# D1H.pdf register map
Vendor: Allwinner; Series: D1H.pdf; File version: 0.1
CPU: XuanTie C906 RISC-V CPU 0, little endian, MPU, FPU, double-precision FPU, 0 interrupt priority bits
Registers are 32-bit, read-write, reset 0x0 unless marked. A register's access mark holds for its fields unless they carry their own. Offsets are from the block's base; [hi:lo] are bit positions; {n}, {i} and the like mark numbered series.

## RTC
Base 0x07090000
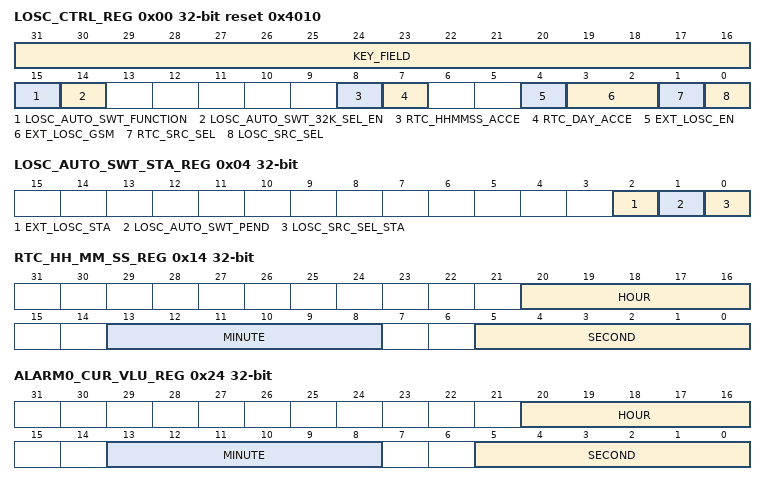
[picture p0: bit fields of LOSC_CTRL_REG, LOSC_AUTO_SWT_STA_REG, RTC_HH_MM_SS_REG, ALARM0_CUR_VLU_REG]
0x00 LOSC_CTRL_REG reset 0x4010 — Low Oscillator Control Register
  [31:16] KEY_FIELD wo — Key Field This field should be filled with 0x16AA, and then the bit0 and bit1 can be written with the new value.
  [15] LOSC_AUTO_SWT_FUNCTION — LOSC auto switch function disable 0: Enable 1: Disable
    0=Enable; 1=Disable
  [14] LOSC_AUTO_SWT_32K_SEL_EN — LOSC auto switch 32K clk source select enable 0: Disable. When the losc losts, the 32k clk source will not change to RC 1: Enable. When the losc losts, the 32k clk source will change to RC (LOSC_SRC_SEL will be changed from 1 to 0)
    0=Disable. When the losc losts, the 32k clk source will not change to RC; 1=Enable. When the losc losts, the 32k clk source will change to RC (LOSC_SRC_SEL will be changed from 1 to 0)
  [8] RTC_HHMMSS_ACCE — RTC Hour Minute Second access After writing the RTC HH-MM-SS Register, this bit is set and it will be cleared until the real writing operation is finished. After writing the RTC HH-MM-SS Register, the RTC HH-MM-SS Register will be refreshed for at most one second. Note: Make sure that the bit is 0 for time configuration.
  [7] RTC_DAY_ACCE — RTC DAY access After writing the RTC DAY register, this bit is set and it will be cleared until the real writing operation is finished. After writing the RTC DAY register, the DAY register will be refreshed for at most one second. Note: Make sure that the bit is 0 for time configuration.
  [4] EXT_LOSC_EN — External 32.768 kHz Crystal Enable 0: Disable 1: Enable
    0=Disable; 1=Enable
  [3:2] EXT_LOSC_GSM — External 32.768 kHz Crystal GSM 00: Low 01: / 10: / 11: High When GSM is changed, the 32K oscillation circuit will arise transient instability. If the autoswitch function (bit 15) is enabled, 32K changes to RC16M with certain probability. The GSM can influence the time of 32K starting oscillation, the more the GSM, the shorter the time of starting oscillation. So modifying GSM is not recommended. If you need to modify the GSM, firstly disable the auto switch function (bit 15), with a delay of 50 us, then change the GSM, the 32K clock source is changed to external clock.
    0=Low; 3=High When GSM is changed, the 32K oscillation circuit will arise transient instability. If the autoswitch function (bit 15) is enabled, 32K changes to RC16M with certain probability. The GSM can influence the time of 32K starting oscillation, the more the GSM, the shorter the time of starting oscillation. So modifying GSM is not recommended. If you need to modify the GSM, firstly disable the auto switch function (bit 15), with a delay of 50 us, then change the GSM, the 32K clock source is changed to external clock.
  [1] RTC_SRC_SEL — RTC_TIMER Clock Source Select 0: LOSC_SRC 1: 24MDIV32K Before switching the bit, make sure that the 24MDIV32K function is enabled, that is, the bit16 of the is 1.
    0=LOSC_SRC; 1=_24MDIV32K (24MDIV32K Before switching the bit, make sure that the 24MDIV32K function is enabled, that is, the bit16 of the is 1.)
  [0] LOSC_SRC_SEL — LOSC Clock Source Select 0: Low frequency clock from 16M RC 1: External 32.768 kHz OSC If the bit[8:7] of LOSC_CTRL_REG is set, the RTC HH-MM-SS, DD and ALARM DD-HH-MM-SS register cannot be written.
    0=Low (Low frequency clock from 16M RC); 1=External 32.768 kHz OSC If the bit[8:7] of LOSC_CTRL_REG is set, the RTC HH-MM-SS, DD and ALARM DD-HH-MM-SS register cannot be written
0x04 LOSC_AUTO_SWT_STA_REG — LOSC Auto Switch Status Register
  [2] EXT_LOSC_STA ro — Work only when the auto switch function is enabled. 0: External 32.768 kHz OSC work normally 1: External 32.768 kHz OSC work abnormally
    0=External_32_point_768_kHz_OSC_work_normally (External 32.768 kHz OSC work normally); 1=External_32_point_768_kHz_OSC_work_abnormally (External 32.768 kHz OSC work abnormally)
  [1] LOSC_AUTO_SWT_PEND write-1-clears — LOSC auto switch pending 0: No effect 1: Auto switch pending, it means LOSC_SRC_SEL is changed from 1 to 0. Setting 1 to this bit will clear it.
    0=No_effect; 1=Auto switch pending, it means LOSC_SRC_SEL is changed from 1 to 0. Setting 1 to this bit will clear it.
  [0] LOSC_SRC_SEL_STA ro — Checking LOSC clock source status 0: Low frequency clock from 16M RC 1: External 32.768 kHz OSC
    0=Low (Low frequency clock from 16M RC); 1=External 32.768 kHz OSC
0x08 INTOSC_CLK_PRESCAL_REG reset 0xF — Internal OSC Clock Pre-scalar Register
  [4:0] INTOSC_32K_CLK_PRESCAL — Internal OSC 32K Clock Prescalar value N. The clock output = Internal RC/32/N. 00000: 1 00001: 2 00002: 3 ............ 11111: 32
    0=_1; 1=_2; 2=_3; 31=_32
0x10 RTC_DAY_REG reset not defined — RTC Year-Month-Day Register
  [15:0] DAY — Set Day Range from 0 to 65535.
0x14 RTC_HH_MM_SS_REG reset not defined — RTC Hour-Minute-Second Register
  [20:16] HOUR — Set hour Range from 0 to 23.
  [13:8] MINUTE — Set minute Range from 0 to 59.
  [5:0] SECOND — Set second Range from 0 to 59.
0x20 ALARM0_DAY_SET_REG — Alarm 0 Day Setting Register
  [15:0] ALARM0_COUNTER — Alarm 0 Counter is based on Day.
0x24 ALARM0_CUR_VLU_REG reset not defined — Alarm 0 Counter Current Value Register
  [20:16] HOUR — Current hour Range from 0 to 23.
  [13:8] MINUTE — Current minute Range from 0 to 59.
  [5:0] SECOND — Current second Range from 0 to 59.
0x28 ALARM0_ENABLE_REG — Alarm 0 Enable Register
  [0] ALM_0_EN — Alarm 0 Enable 0: Disable 1: Enable
    0=Disable; 1=Enable
0x2C ALARM0_IRQ_EN — Alarm 0 IRQ Enable Register
  [0] ALARM0_IRQ_EN — Alarm 0 IRQ Enable 0: Disable 1: Enable
    0=Disable; 1=Enable
0x30 ALARM0_IRQ_STA_REG — Alarm 0 IRQ Status Register
  [0] ALARM0_IRQ_PEND write-1-clears — Alarm 0 IRQ Pending bit 0: No effect 1: Pending, alarm 0 counter value is reached If alarm 0 irq enable is set to 1, the pending bit will be sent to the interrupt controller.
    0=No_effect; 1=Pending, alarm 0 counter value is reached If alarm 0 irq enable is set to 1, the pending bit will be sent to the interrupt controller
0x50 ALARM_CONFIG_REG — Alarm Configuration Register
  [0] ALARM_WAKEUP — Configuration of alarm wake up output. 0: Disable alarm wake up output 1: Enable alarm wake up output
    0=Disable alarm wake up output; 1=Enable alarm wake up output
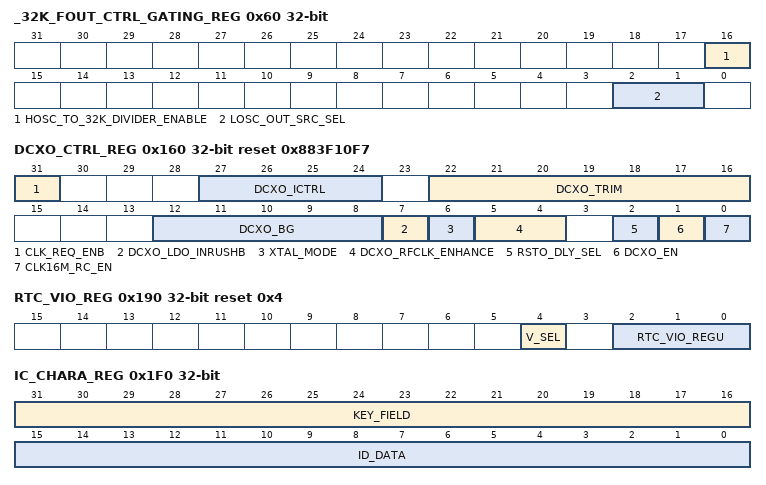
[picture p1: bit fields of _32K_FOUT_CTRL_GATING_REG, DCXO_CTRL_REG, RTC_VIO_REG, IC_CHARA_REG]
0x60 _32K_FOUT_CTRL_GATING_REG
  [16] HOSC_TO_32K_DIVIDER_ENABLE — HOSC to 32k divider enable 0: Disable the hosc 24M to 32K divider circuit 1: Enable the hosc 24M to 32K divider circuit
    0=Disable the hosc 24M to 32K divider circuit; 1=Enable the hosc 24M to 32K divider circuit
  [2:1] LOSC_OUT_SRC_SEL — LOSC output source select 00: RTC_32K (select by RC_CLK_SRC_SEL & LOSC_SRC_SEL) 01: LOSC 10: HOSC divided 32K
    0=RTC_32K (RTC_32K (select by RC_CLK_SRC_SEL & LOSC_SRC_SEL)); 1=LOSC; 2=HOSC (HOSC divided 32K)
{0x100+4i} GP_DATA_REGN[{i}] (i=0..7) — GP_DATA_REGN[{i}]
  [31:0] GP_DATA — Data [31:0] General purpose register 0 to 7 value can be stored if the RTC-VIO is larger than 0.7 V.
0x120 FBOOT_INFO_REG0 — Fast Boot Information Register0
  [31:0] FBOOT_INFO0 — Fast Boot info Fast Boot Information 0, refer to BROM spec.
0x124 FBOOT_INFO_REG1 — Fast Boot Information Register1
  [31:0] FBOOT_INFO1 — Fast Boot info Fast Boot Information 1, refer to BROM spec.
0x160 DCXO_CTRL_REG reset 0x883F10F7 — DCXO Control Register
  [31] CLK_REQ_ENB — Clock REQ enable 0: Enable DCXO wake up function 1: Disable DCXO wake up function
    0=Enable DCXO wake up function; 1=Disable DCXO wake up function
  [27:24] DCXO_ICTRL — DCXO current control value
  [22:16] DCXO_TRIM — DCXO cap array value The capacity cell is 55 fF.
  [12:8] DCXO_BG — DCXO bandgap output voltage
  [7] DCXO_LDO_INRUSHB — DCXO LDO driving capacity signal, active high
  [6] XTAL_MODE — Xtal mode enable signal, active high 0: For external clk input mode 1: For normal mode
    0=For external clk input mode; 1=For_normal_mode
  [5:4] DCXO_RFCLK_ENHANCE — DCXO rfclk enhance Enhance driving capacity of output OUT_RF_REFCLK, 0x0 for 5 pF, 0x1 for 10 pF, 0x2 for 15 pF, 0x3 for 20 pF.
  [2] RSTO_DLY_SEL — For Debug Use Only. It cannot configure to 0 in normal state.
  [1] DCXO_EN — DCXO enable 1: Enable 0: Disable
    1=Enable; 0=Disable
  [0] CLK16M_RC_EN — 1: Enable 0: Disable The related register configuration is necessary to ensure the reset debounce circuit has a stable clock source. The first time SoC starts up, by default, the reset debounce circuit of SoC uses 32K divided by RC16M. In power-off, software reads the related bit to ensure whether EXT32K is working normally, if it is normal, first switch the clock source of debounce circuit to EXT32K, then close RC16M. Without EXT32K scenario or external RTC scenario, software confirms firstly whether EXT32K is working normally before switching, or software does not close RC16M.
    1=Enable; 0=Disable The related register configuration is necessary to ensure the reset debounce circuit has a stable clock source. The first time SoC starts up, by default, the reset debounce circuit of SoC uses 32K divided by RC16M. In power-off, software reads the related bit to ensure whether EXT32K is working normally, if it is normal, first switch the clock source of debounce circuit to EXT32K, then close RC16M. Without EXT32K scenario or external RTC scenario, software confirms firstly whether EXT32K is working normally before switching, or software does not close RC16M.
0x190 RTC_VIO_REG reset 0x4 — RTC_VIO Regulation Register
  [4] V_SEL — VDD Select 0: Resistance divider 1: Band gap
    0=Resistance divider; 1=Band gap
  [2:0] RTC_VIO_REGU — RTC_VIO Voltage Select The RTC-VIO is provided power for RTC digital part. These bits are useful for regulating the RTC_VIO from 0.65 V to 1.3 V. 000: 1.0 V 001: 0.65 V (the configuration can cause RTC reset) 010: 0.7 V 011: 0.8 V 100: 0.9 V 101: 1.1 V 110: 1.2 V 111: 1.3 V
    0=_1_point_0_V (1.0 V); 1=_0_point_65_V (0.65 V (the configuration can cause RTC reset)); 2=_0_point_7_V (0.7 V); 3=_0_point_8_V (0.8 V); 4=_0_point_9_V (0.9 V); 5=_1_point_1_V (1.1 V); 6=_1_point_2_V (1.2 V); 7=_1_point_3_V (1.3 V)
0x1F0 IC_CHARA_REG — IC Characteristic Register
  [31:16] KEY_FIELD — Key Field The field should be written as 0x16AA. Writing any other value in this field aborts the write-operation.
  [15:0] ID_DATA — Return 0x16AA only if the KEY_FIELD is set as 0x16AA when read those bits, otherwise return 0x0.
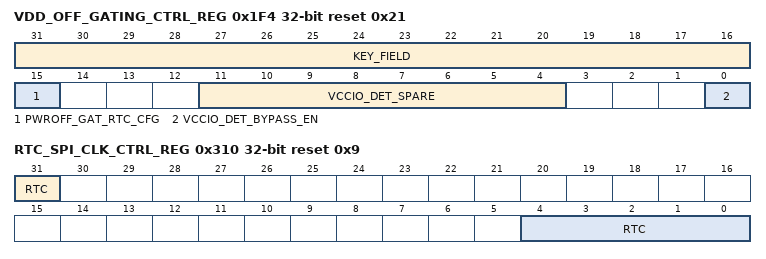
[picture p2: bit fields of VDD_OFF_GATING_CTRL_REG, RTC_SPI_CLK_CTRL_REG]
0x1F4 VDD_OFF_GATING_CTRL_REG reset 0x21 — VDD Off Gating Control Register
  [31:16] KEY_FIELD wo — Key Field This field should be filled with 0x16AA, and then the bit 15 can be configured.
  [15] PWROFF_GAT_RTC_CFG wo — (For Debug Use Only) Power off gating control signal When use vdd_sys to RTC isolation software control, write this bit to 1. It will only be cleared by resetb release.
  [11:4] VCCIO_DET_SPARE — Bit[7:5]: Reserved, default=0 Bit[4]: Bypass debounce circuit, defaule=0 Bit[3]: Enable control, defaule=0 0: Disable VCC-IO detection 1: Force the detection output Bit[2:0]: Gear adjustment 000: Detection threshold is 2.5 V 001: Detection threshold is 2.6 V 010: Detection threshold is 2.7 V (default) 011: Detection threshold is 2.8 V 100: Detection threshold is 2.9 V 101: Detection threshold is 3 V 110: N/A 111: N/A
  [0] VCCIO_DET_BYPASS_EN — 0: not bypass 1: bypass
    0=not_bypass; 1=bypass
0x204 EFUSE_HV_PWRSWT_CTRL_REG
  [0] EFUSE_1_8V_POWER_SWITCH_CONTROL — 1: Open power switch 0: Close power switch
    1=Open power switch; 0=Close power switch
0x310 RTC_SPI_CLK_CTRL_REG reset 0x9 — RTC SPI Clock Control Register The offset addresses less than 0x0300 are in VDD_RTC power domain, and the offset addresses large than or equal to 0x300 are in VDD_SYS power domain.
  [31] RTC — Reg CFG SPI Clock Gating 0: Gating 1: Not Gating Before configurating RTC register, the clock divider of SPI needs be configured firstly, then clock gating needs be enabled. Note: Frequency division and clock gating can not be set at the same time.
    0=Gating; 1=Not Gating Before configurating RTC register, the clock divider of SPI needs be configured firstly, then clock gating needs be enabled. Note: Frequency division and clock gating can not be set at the same time.
  [4:0] RTC — Reg CFG SPI Clock Divider: M Actual SPI Clock = AHBS1/(M+1), (0 to 15) The default frequency of AHBS1 is 200 MHz, and the default frequency of SPI Clock is 20 MHz. Note: The SPI clock can not exceed 50 MHz, or else the RTC register may be abnormal. 4 Video and Graphics ................................................................................................................................................. 381 4.1 DE .................................................................................................................................................................... 381 4.2 DI ..................................................................................................................................................................... 382 4.3 G2D.................................................................................................................................................................. 383 4.4 Video Decoding ............................................................................................................................................... 384 4.4.1 Overview ............................................................................................................................................. 384 4.4.2 Block Diagram ..................................................................................................................................... 385 4.5 Video Encoding ............................................................................................................................................... 386 4.5.1 Overview ............................................................................................................................................. 386 4.5.2 Block Diagram ..................................................................................................................................... 386 Figure 4-1 DE Block Diagram ............................................................................................................................................. 381 Figure 4-2 Video Decoding Block Diagram ........................................................................................................................ 385 Figure 4-3 JPGE Block Diagram ......................................................................................................................................... 387 The Display Engine (DE) is a hardware composer to transfer image layers from a local bus or a video buffer to the LCD interface. The DE supports four overlay windows to blend, and supports image post-processing in the video channel. The block diagram of DE is shown in Figure 4-1. The DE has the following features: Output size up to 2048 x 2048 Four alpha blending channels for main display, three channels for aux display Four overlay layers in each channel, and has a independent scaler Potter-duff compatible blending operation Support input format Semi-planar YUV422/YUV420/YUV411 and Planar YUV422/YUV420/YUV411, ARGB8888/XRGB8888/RGB888/ARGB4444/ARGB1555/RGB565/palette Supports SmartColor2.0 for excellent display experience - Adaptive detail/edge enhancement - Adaptive color enhancement - Adaptive contrast enhancement and fresh tone rectify Supports write back for aux display The De-interlacer (DI) converts the interlaced input video frame to progressive video frame. The DI has the following features: Supports YUV420 (Planar/NV12/NV21) and YUV422 (Planar/NV16/NV61) data format Supports video resolution from 32x32 to 2048x1280 pixel Supports Inter-field interpolation/motion adaptive de-interlace method Performance: module clock 600M for 1080p@60Hz YUV420 The Graphic 2D (G2D) engine is hardware accelerator for 2D graphic. The G2D has the following features: Supports layer size up to 2048 x 2048 pixels Supports pre-multiply alpha image data Supports color key Supports two pipes Porter-Duff alpha blending Supports multiple video formats 4:2:0, 4:2:2, 4:1:1 and multiple pixel formats (8/16/24/32 bits graphics layer) Supports memory scan order option Supports any format convert function Supports 1/16× to 32× resize ratio Supports 32-phase 8-tap horizontal anti-alias filter and 32-phase 4-tap vertical anti-alias filter Supports window clip Supports FillRectangle, BitBlit, StretchBlit and MaskBlit Supports horizontal and vertical flip, clockwise 0/90/180/270 degree rotate for normal buffer Supports horizontal flip, clockwise 0/90/270 degree rotate for LBC buffer
